# trng_reva register map
Registers are access not given, reset 0xFFFFFFC0 unless marked. A register's access mark holds for its fields unless they carry their own. Offsets are from the block's base; lines under a group give offsets from that group; [hi:lo] are bit positions; {n}, {i} and the like mark numbered series; 'fields as' and 'values as' point back to an identical list; <NAME> marks a mode.

## Memory map
0x400B5000 TRNG size 0x1000 — Random Number Generator.

## Interrupts
4 TRNG — TRNG interrupt.

## TRNG — Random Number Generator.
Base 0x400B5000
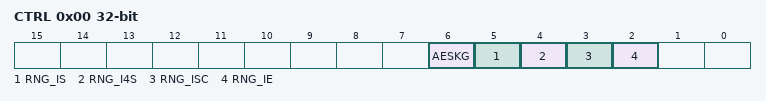
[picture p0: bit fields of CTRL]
0x00 CTRL — TRNG Control Register.
  [6] AESKG — When enabled, the key for securing NVSRAM is generated and transferred to the secure key register automatically without user visibility or intervention. This bit is cleared by hardware once the key has been transferred to the secure key register.
  [5] RNG_IS — This bit is set when a new 32 bit random number is available in TRNG_DATA.
    0=not_ready (32-bit random number not ready.); 1=ready (32-bit random number ready.)
  [4] RNG_I4S — This bit is set when a new 128 bit random number is ready to be read (using 4 consecutive reads of TRNG_DATA. When set, an interrupt will be generated if TRNG_CTRL.rng_ie = 1. This bit is cleared by setting TRNG_CTRL.rng_isc.
    0=not_ready (128-bit random number not ready.); 1=ready (128-bit random number ready.)
  [3] RNG_ISC — Clears the RNG interrupt occuring after an 128-bit random number is ready.
    1=Clear the RNG interrupt
  [2] RNG_IE — To enable IRQ generation when a new 32-bit Random number is ready.
    0=dis (Disable); 1=en (Enable)
0x04 DATA ro reset not defined — Data. The content of this register is valid only when RNG_IS = 1. When TRNG is disabled, read returns 0x0000 0000.
  [31:0] DATA — Data. The content of this register is valid only when RNG_IS =1. When TNRG is disabled, read returns 0x0000 0000.
